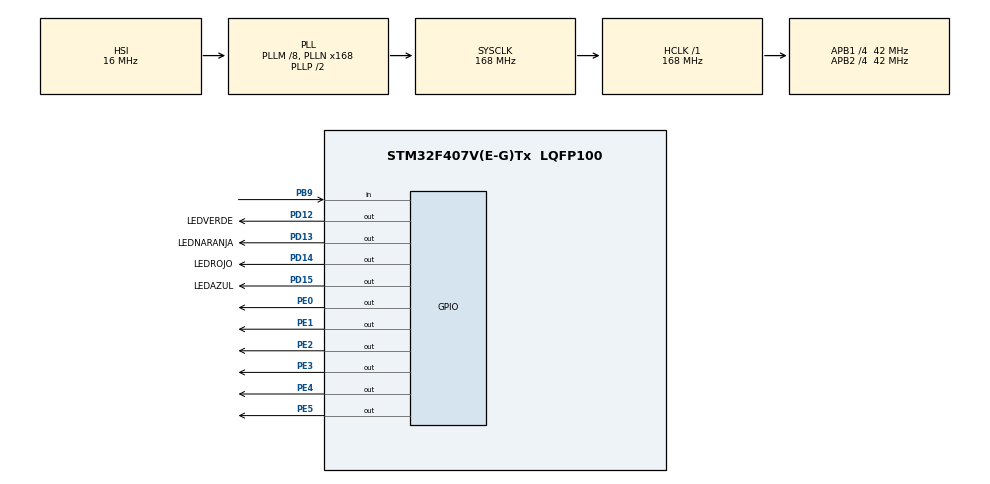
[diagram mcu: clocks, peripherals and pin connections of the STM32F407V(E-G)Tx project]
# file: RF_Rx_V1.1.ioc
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Mcu.Family=STM32F4
Mcu.Name=STM32F407V(E-G)Tx
Mcu.Package=LQFP100
NVIC.PriorityGroup=NVIC_PRIORITYGROUP_0
PB9.Signal=GPIO_Input
PD12.GPIO_Label=LEDVERDE
PD12.Signal=GPIO_Output
PD13.GPIO_Label=LEDNARANJA
PD13.Signal=GPIO_Output
PD14.GPIO_Label=LEDROJO
PD14.Signal=GPIO_Output
PD15.GPIO_Label=LEDAZUL
PD15.Signal=GPIO_Output
PE0.Signal=GPIO_Output
PE1.Signal=GPIO_Output
PE2.Signal=GPIO_Output
PE3.Signal=GPIO_Output
PE4.Signal=GPIO_Output
PE5.Signal=GPIO_Output
PH0-OSC_IN.Signal=RCC_OSC_IN
PH1-OSC_OUT.Signal=RCC_OSC_OUT
ProjectManager.HeapSize=0x200
ProjectManager.StackSize=0x400
ProjectManager.TargetToolchain=SW4STM32
RCC.48MHZClocksFreq_Value=48000000
RCC.AHBFreq_Value=168000000
RCC.APB1CLKDivider=RCC_HCLK_DIV4
RCC.APB1Freq_Value=42000000
RCC.APB1TimFreq_Value=84000000
RCC.APB2CLKDivider=RCC_HCLK_DIV4
RCC.APB2Freq_Value=42000000
RCC.APB2TimFreq_Value=84000000
RCC.CortexFreq_Value=168000000
RCC.HCLKFreq_Value=168000000
RCC.HSE_VALUE=8000000
RCC.HSI_VALUE=16000000
RCC.LSE_VALUE=32768
RCC.PLLM=8
RCC.PLLN=168
RCC.PLLQ=7
RCC.SYSCLKFreq_VALUE=168000000
RCC.SYSCLKSource=RCC_SYSCLKSOURCE_PLLCLK
RCC.VCOOutputFreq_Value=336000000
board=STM32F407G-DISC1

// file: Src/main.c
/* USER CODE BEGIN Header */
/**
  ******************************************************************************
  * @file           : main.c
  * @brief          : Main program body
  ******************************************************************************
  * @attention
  *
  * <h2><center>&copy; Copyright (c) 2019 STMicroelectronics.
  * All rights reserved.</center></h2>
  *
  * This software component is licensed by ST under BSD 3-Clause license,
  * the "License"; You may not use this file except in compliance with the
  * License. You may obtain a copy of the License at:
  *                        opensource.org/licenses/BSD-3-Clause
  *
  ******************************************************************************
  */
/* USER CODE END Header */

#include "main.h"
#include "lcd_txt.h"
#include "math.h"
#include "stdio.h"

void SystemClock_Config(void);
static void MX_GPIO_Init(void);

/* USER CODE BEGIN 0 */
//int ByteInicio[8];
//int ByteDato[8];
int TramaTotal[16];
int cont;
int ByteInicioNoValido=1;
int ValorDecimal, Paridad;
int r;
char buffer[6];
/* USER CODE END 0 */

int main(void)
{

  /* MCU Configuration--------------------------------------------------------*/

  /* Reset of all peripherals, Initializes the Flash interface and the Systick. */
  HAL_Init();

  /* Configure the system clock */
  SystemClock_Config();

  /* Initialize all configured peripherals */
  MX_GPIO_Init();
  /* USER CODE BEGIN 2 */
  lcd_init();
  /* USER CODE END 2 */

  /* Infinite loop */
  while (1) {
	  HAL_Delay(50);
	  //lcd_clear();
	  lcd_puts(0,0,(int8_t*)"Temperatura:");
	  //HAL_GPIO_WritePin(GPIOD, GPIO_PIN_13, GPIO_PIN_SET);
	  while (ByteInicioNoValido){
	    //	  HAL_Delay(10);

	      /* Lleno un array y continúa el programa solo si recibí el byte de inicio */
	    	  for(cont=0;cont<16;cont++){

	    		  TramaTotal[cont]=HAL_GPIO_ReadPin(GPIOB, GPIO_PIN_9);
	    		  HAL_Delay(20);

	    	  }

	    	  HAL_GPIO_WritePin(GPIOD, GPIO_PIN_13, GPIO_PIN_SET);
	    	  HAL_Delay(20);
	    	  HAL_GPIO_WritePin(GPIOD, GPIO_PIN_13, GPIO_PIN_RESET);

	    	  if(TramaTotal[0]==0 &&
	    		 TramaTotal[1]==1 &&
	    		 TramaTotal[2]==0 &&
	    		 TramaTotal[3]==0 &&
	    		 TramaTotal[4]==0 &&
	    		 TramaTotal[5]==1 &&
	    		 TramaTotal[6]==1 &&
	    		 TramaTotal[7]==0)
	    	  	  	  	  	  	  {
	    		  HAL_GPIO_WritePin(GPIOD, GPIO_PIN_14, GPIO_PIN_SET);
	    		  HAL_Delay(100);
	    		  HAL_GPIO_WritePin(GPIOD, GPIO_PIN_14, GPIO_PIN_RESET);
	    		  int SumaParidad=0,p;
	    		  	for(p=14;p>=8;p--){
	    		  		if(TramaTotal[p]==1){
	    		  			SumaParidad=SumaParidad+1;
	    		  		}
	    		  	}
	    		  	Paridad=SumaParidad%2;
	    		  	if(TramaTotal[15]==Paridad){
	    		  		ByteInicioNoValido=0;		//Si coinciden el byte de inicio y la paridad es correcta sale del while de recepción
	    		  		HAL_GPIO_WritePin(GPIOD, GPIO_PIN_12, GPIO_PIN_SET);
	    		  		HAL_Delay(100);
	    		  		HAL_GPIO_WritePin(GPIOD, GPIO_PIN_12, GPIO_PIN_RESET);

	    		  	}

	    	  	  	  	  	  	  }

	      }//llave while byte inicio no válido
	    int potencia=6;
	      	  	 ValorDecimal=0;
	        	 for(cont=8;cont<15;cont++){
	        	   	if(TramaTotal[cont]==1){	//Convierte el array binario al valor decimal r
	        	   								//cont daría la posición del array
	        	   		r=pow(2,(potencia));

	        	  			ValorDecimal=ValorDecimal+r;
	        	  		}
	        	   	potencia--;
	        	   }//llave for conversion bin-dec

	        	 sprintf(buffer,"%d",ValorDecimal);			//convierto el valor a una cadena de caracteres
	        	 lcd_puts(1,0,(int8_t*)"        Grados C");				//Borro los posibles dígitos sobrantes
	        	 lcd_puts(1,4,(int8_t*)buffer);				//imprimo en pantalla la cadena

	        	 ByteInicioNoValido=1;
	      	  }//llave while programa
  }

void SystemClock_Config(void)
{
  RCC_OscInitTypeDef RCC_OscInitStruct = {0};
  RCC_ClkInitTypeDef RCC_ClkInitStruct = {0};

  /** Configure the main internal regulator output voltage
  */
  __HAL_RCC_PWR_CLK_ENABLE();
  __HAL_PWR_VOLTAGESCALING_CONFIG(PWR_REGULATOR_VOLTAGE_SCALE1);
  /** Initializes the CPU, AHB and APB busses clocks
  */
  RCC_OscInitStruct.OscillatorType = RCC_OSCILLATORTYPE_HSI;
  RCC_OscInitStruct.HSIState = RCC_HSI_ON;
  RCC_OscInitStruct.HSICalibrationValue = RCC_HSICALIBRATION_DEFAULT;
  RCC_OscInitStruct.PLL.PLLState = RCC_PLL_ON;
  RCC_OscInitStruct.PLL.PLLSource = RCC_PLLSOURCE_HSI;
  RCC_OscInitStruct.PLL.PLLM = 8;
  RCC_OscInitStruct.PLL.PLLN = 168;
  RCC_OscInitStruct.PLL.PLLP = RCC_PLLP_DIV2;
  RCC_OscInitStruct.PLL.PLLQ = 7;
  if (HAL_RCC_OscConfig(&RCC_OscInitStruct) != HAL_OK)
  {
    Error_Handler();
  }
  /** Initializes the CPU, AHB and APB busses clocks
  */
  RCC_ClkInitStruct.ClockType = RCC_CLOCKTYPE_HCLK|RCC_CLOCKTYPE_SYSCLK
                              |RCC_CLOCKTYPE_PCLK1|RCC_CLOCKTYPE_PCLK2;
  RCC_ClkInitStruct.SYSCLKSource = RCC_SYSCLKSOURCE_PLLCLK;
  RCC_ClkInitStruct.AHBCLKDivider = RCC_SYSCLK_DIV1;
  RCC_ClkInitStruct.APB1CLKDivider = RCC_HCLK_DIV4;
  RCC_ClkInitStruct.APB2CLKDivider = RCC_HCLK_DIV4;

  if (HAL_RCC_ClockConfig(&RCC_ClkInitStruct, FLASH_LATENCY_5) != HAL_OK)
  {
    Error_Handler();
  }
}

static void MX_GPIO_Init(void)
{
  GPIO_InitTypeDef GPIO_InitStruct = {0};

  /* GPIO Ports Clock Enable */
  __HAL_RCC_GPIOE_CLK_ENABLE();
  __HAL_RCC_GPIOH_CLK_ENABLE();
  __HAL_RCC_GPIOD_CLK_ENABLE();
  __HAL_RCC_GPIOB_CLK_ENABLE();

  /*Configure GPIO pin Output Level */
  HAL_GPIO_WritePin(GPIOE, GPIO_PIN_2|GPIO_PIN_3|GPIO_PIN_4|GPIO_PIN_5
                          |GPIO_PIN_0|GPIO_PIN_1, GPIO_PIN_RESET);

  /*Configure GPIO pin Output Level */
  HAL_GPIO_WritePin(GPIOD, LEDVERDE_Pin|LEDNARANJA_Pin|LEDROJO_Pin|LEDAZUL_Pin, GPIO_PIN_RESET);

  /*Configure GPIO pins : PE2 PE3 PE4 PE5
                           PE0 PE1 */
  GPIO_InitStruct.Pin = GPIO_PIN_2|GPIO_PIN_3|GPIO_PIN_4|GPIO_PIN_5
                          |GPIO_PIN_0|GPIO_PIN_1;
  GPIO_InitStruct.Mode = GPIO_MODE_OUTPUT_PP;
  GPIO_InitStruct.Pull = GPIO_NOPULL;
  GPIO_InitStruct.Speed = GPIO_SPEED_FREQ_LOW;
  HAL_GPIO_Init(GPIOE, &GPIO_InitStruct);

  /*Configure GPIO pins : LEDVERDE_Pin LEDNARANJA_Pin LEDROJO_Pin LEDAZUL_Pin */
  GPIO_InitStruct.Pin = LEDVERDE_Pin|LEDNARANJA_Pin|LEDROJO_Pin|LEDAZUL_Pin;
  GPIO_InitStruct.Mode = GPIO_MODE_OUTPUT_PP;
  GPIO_InitStruct.Pull = GPIO_NOPULL;
  GPIO_InitStruct.Speed = GPIO_SPEED_FREQ_LOW;
  HAL_GPIO_Init(GPIOD, &GPIO_InitStruct);

  /*Configure GPIO pin : PB9 */
  GPIO_InitStruct.Pin = GPIO_PIN_9;
  GPIO_InitStruct.Mode = GPIO_MODE_INPUT;
  GPIO_InitStruct.Pull = GPIO_NOPULL;
  HAL_GPIO_Init(GPIOB, &GPIO_InitStruct);

}

void Error_Handler(void)
{
}

/************************ (C) COPYRIGHT STMicroelectronics *****END OF FILE****/
